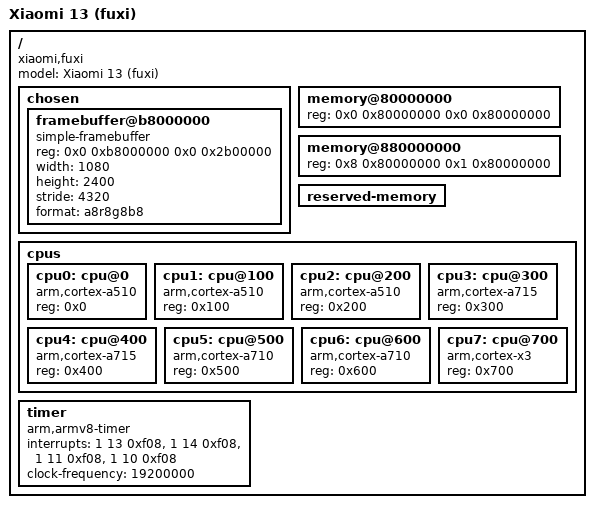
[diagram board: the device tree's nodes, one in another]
/dts-v1/;

/*
 * Minimal fuxi (Xiaomi 13, SM8550) board tree for the UniXNU boot image.
 *
 * This is NOT the full hardware description - it exists to satisfy two things
 * at fastboot-boot time:
 *   1. the stock ABL only keeps the display pipeline enabled when the appended
 *      DT carries a reserved-memory node named exactly "splash_region" (same
 *      trap sheng documents; this port hit it independently - the panel powers
 *      off without it), and
 *   2. UniXNU/UEFI want a tree with the memory node and a model string.
 *
 * Addresses are fuxi's own, read from the live device tree and iomem:
 *   splash_region 0x0b8000000 + 0x002b00000 (43 MiB)  - VERIFIED
 *   DRAM banks 0x80000000 + 2 GiB, 0x880000000 + 6 GiB (8 GB unit)
 */

/ {
	model = "Xiaomi 13 (fuxi)";
	compatible = "xiaomi,fuxi", "qcom,sm8550";
	#address-cells = <2>;
	#size-cells = <2>;

	chosen {
		#address-cells = <2>;
		#size-cells = <2>;

		framebuffer@b8000000 {
			compatible = "simple-framebuffer";
			reg = <0x0 0xb8000000 0x0 0x2b00000>;
			width = <1080>;
			height = <2400>;
			stride = <4320>;	/* 1080 * 4, a8r8g8b8 */
			format = "a8r8g8b8";
		};
	};

	memory@80000000 {
		device_type = "memory";
		reg = <0x0 0x80000000 0x0 0x80000000>;
	};

	memory@880000000 {
		device_type = "memory";
		reg = <0x8 0x80000000 0x1 0x80000000>;	/* 6 GiB at 0x880000000 */
	};

	reserved-memory {
		#address-cells = <2>;
		#size-cells = <2>;
		ranges;
		/*
		 * No splash_region here: the build driver injects it from
		 * [[bootimg.dtb_node]] in board.toml, and fdtput fails with
		 * FDT_ERR_EXISTS if the blob already carries the node.
		 */
	};

	cpus {
		#address-cells = <1>;
		#size-cells = <0>;

		cpu0: cpu@0 { device_type = "cpu"; compatible = "arm,cortex-a510"; reg = <0x0>; };
		cpu1: cpu@100 { device_type = "cpu"; compatible = "arm,cortex-a510"; reg = <0x100>; };
		cpu2: cpu@200 { device_type = "cpu"; compatible = "arm,cortex-a510"; reg = <0x200>; };
		cpu3: cpu@300 { device_type = "cpu"; compatible = "arm,cortex-a715"; reg = <0x300>; };
		cpu4: cpu@400 { device_type = "cpu"; compatible = "arm,cortex-a715"; reg = <0x400>; };
		cpu5: cpu@500 { device_type = "cpu"; compatible = "arm,cortex-a710"; reg = <0x500>; };
		cpu6: cpu@600 { device_type = "cpu"; compatible = "arm,cortex-a710"; reg = <0x600>; };
		cpu7: cpu@700 { device_type = "cpu"; compatible = "arm,cortex-x3"; reg = <0x700>; };
	};

	timer {
		compatible = "arm,armv8-timer";
		interrupts = <1 13 0xf08>, <1 14 0xf08>,
			     <1 11 0xf08>, <1 10 0xf08>;
		clock-frequency = <19200000>;
	};
};
